# HDSC_HC32L110 register map
Vendor: HDSC Co.Ltd; Series: ARMCM0P; File version: 1.2
CPU: CM0 r0p0, little endian, no MPU, no FPU, 3 interrupt priority bits
Registers are 32-bit, read-write, reset 0x0 unless marked. A register's access mark holds for its fields unless they carry their own. Offsets are from the block's base; [hi:lo] are bit positions; {n}, {i} and the like mark numbered series; 'fields as' and 'values as' point back to an identical list.

## I2C
Base 0x40000400
0x00 TMRUN
  [0] TME
0x04 TM
  [7:0] TM
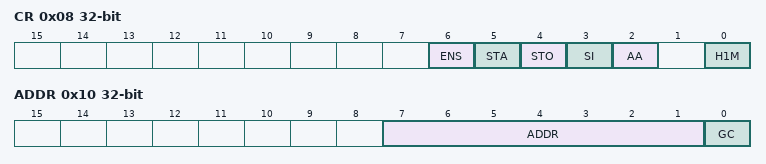
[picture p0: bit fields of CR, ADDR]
0x08 CR
  [6] ENS, [5] STA, [4] STO, [3] SI, [2] AA, [0] H1M
0x0C DATA
  [7:0] DATA
0x10 ADDR
  [7:1] ADDR, [0] GC
0x14 STAT ro
  [7:0] STAT

## LPTIMER
Base 0x40000C00; alternate view of BT0
0x60 CNT ro
  [15:0] CNT
0x64 ARR
  [15:0] ARR
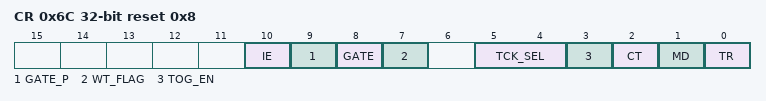
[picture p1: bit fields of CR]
0x6C CR reset 0x8
  [10] IE, [9] GATE_P, [8] GATE, [7] WT_FLAG ro, [5:4] TCK_SEL, [3] TOG_EN, [2] CT, [1] MD, [0] TR
0x70 IFR ro
  [0] TF
0x74 ICLR wo
  [0] TFC

## LPUART
Base 0x40000200
0x00 SBUF
  [7:0] SBUF
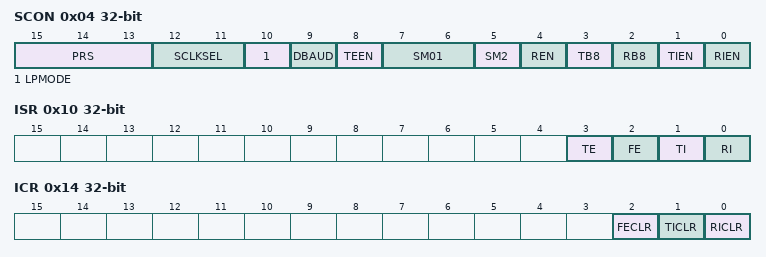
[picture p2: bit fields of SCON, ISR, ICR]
0x04 SCON
  [15:13] PRS, [12:11] SCLKSEL, [10] LPMODE, [9] DBAUD, [8] TEEN, [7:6] SM01, [5] SM2, [4] REN, [3] TB8, [2] RB8, [1] TIEN, [0] RIEN
0x08 SADDR
  [7:0] SADDR
0x0C SADEN
  [7:0] SADEN
0x10 ISR ro
  [3] TE, [2] FE, [1] TI, [0] RI
0x14 ICR wo
  [2] FECLR, [1] TICLR, [0] RICLR

## LVD
Base 0x40002400; alternate view of ADC
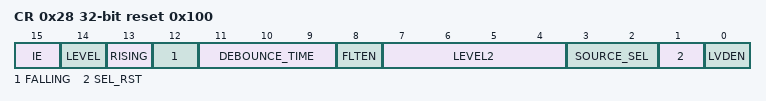
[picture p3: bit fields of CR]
0x28 CR reset 0x100
  [15] IE, [14] LEVEL, [13] RISING, [12] FALLING, [11:9] DEBOUNCE_TIME, [8] FLTEN, [7:4] LEVEL2, [3:2] SOURCE_SEL, [1] SEL_RST, [0] LVDEN
0x2C IFR
  [0] INTF

## PCA
Base 0x40001000
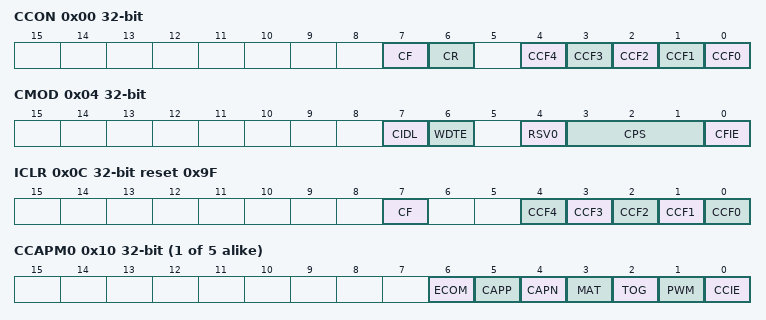
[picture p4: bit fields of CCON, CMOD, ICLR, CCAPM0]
0x00 CCON
  [7] CF, [6] CR, [n] CCF{n} (n=0..4)
0x04 CMOD
  [7] CIDL, [6] WDTE, [4] RSV0, [3:1] CPS, [0] CFIE
0x08 CNT
  [15:0] CNT
0x0C ICLR wo reset 0x9F
  [7] CF, [n] CCF{n} (n=0..4)
{0x10+4i} CCAPM{i} (i=0..4)
  [6] ECOM, [5] CAPP, [4] CAPN, [3] MAT, [2] TOG, [1] PWM, [0] CCIE
{0x24+8i} CCAP{i}H (i=0..4)
  [7:0] CCAP{i}
{0x28+8i} CCAP{i}L (i=0..4)
  [7:0] CCAP{i}
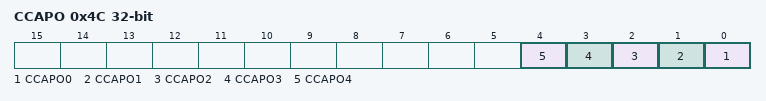
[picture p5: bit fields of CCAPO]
0x4C CCAPO
  [n] CCAPO{n} (n=0..4)
{0x50+4i} CCAP{i} (i=0..4)
  [15:0] CCAP{i}

## RAM
Base 0x40020400
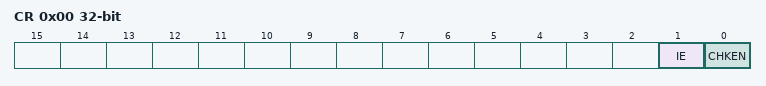
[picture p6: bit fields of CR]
0x00 CR
  [1] IE, [0] CHKEN
0x04 ERRADDR ro
  [11:0] ERRADDR
0x08 IFR ro
  [0] ERR
0x0C ICLR ro
  [0] ERRCLR wo

## RESET
Base 0x4000201C
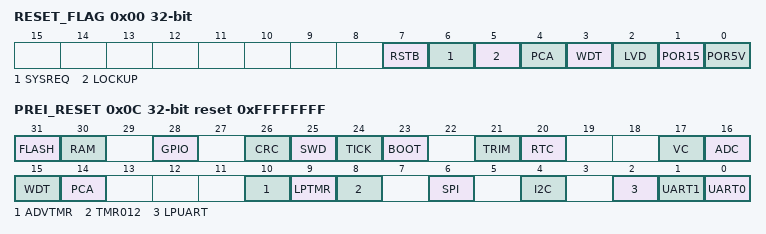
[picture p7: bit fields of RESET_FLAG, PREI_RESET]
0x00 RESET_FLAG
  [7] RSTB, [6] SYSREQ, [5] LOCKUP, [4] PCA, [3] WDT, [2] LVD, [1] POR15, [0] POR5V
0x0C PREI_RESET reset 0xFFFFFFFF
  [31] FLASH, [30] RAM, [28] GPIO, [26] CRC, [25] SWD, [24] TICK, [23] BOOT, [21] TRIM, [20] RTC, [17] VC, [16] ADC, [15] WDT, [14] PCA, [10] ADVTMR, [9] LPTMR, [8] TMR012, [6] SPI, [4] I2C, [2] LPUART, [1] UART1, [0] UART0

## RTC
Base 0x40001400
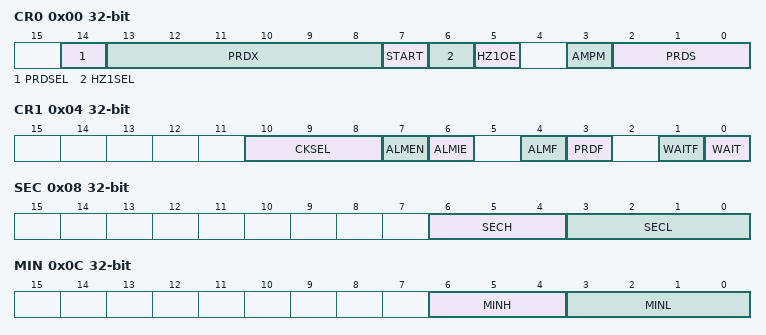
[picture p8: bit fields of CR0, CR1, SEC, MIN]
0x00 CR0
  [14] PRDSEL, [13:8] PRDX, [7] START, [6] HZ1SEL, [5] HZ1OE, [3] AMPM, [2:0] PRDS
0x04 CR1
  [10:8] CKSEL, [7] ALMEN, [6] ALMIE, [4] ALMF, [3] PRDF, [1] WAITF, [0] WAIT
0x08 SEC
  [6:4] SECH, [3:0] SECL
0x0C MIN
  [6:4] MINH, [3:0] MINL
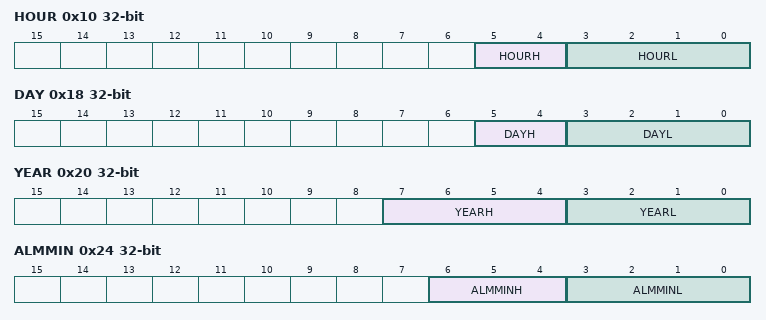
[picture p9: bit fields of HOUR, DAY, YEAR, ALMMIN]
0x10 HOUR
  [5:4] HOURH, [3:0] HOURL
0x14 WEEK
  [2:0] WEEK
0x18 DAY
  [5:4] DAYH, [3:0] DAYL
0x1C MON
  [4:0] MON
0x20 YEAR
  [7:4] YEARH, [3:0] YEARL
0x24 ALMMIN
  [6:4] ALMMINH, [3:0] ALMMINL
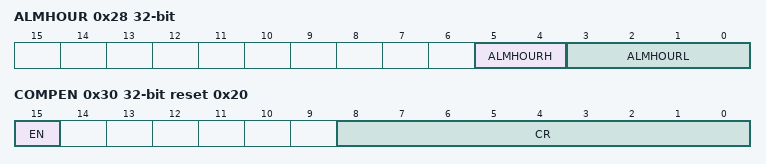
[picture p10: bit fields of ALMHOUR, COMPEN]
0x28 ALMHOUR
  [5:4] ALMHOURH, [3:0] ALMHOURL
0x2C ALMWEEK
  [6:0] ALMWEEK
0x30 COMPEN reset 0x20
  [15] EN, [8:0] CR

## SPI
Base 0x40000800
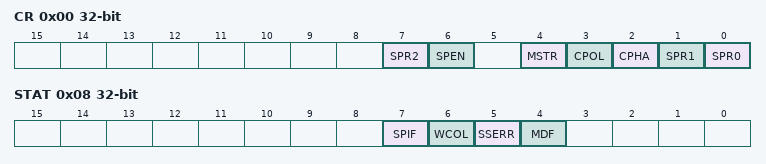
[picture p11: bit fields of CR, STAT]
0x00 CR
  [7] SPR2, [6] SPEN, [4] MSTR, [3] CPOL, [2] CPHA, [1] SPR1, [0] SPR0
0x04 SSN
  [0] SSN
0x08 STAT ro
  [7] SPIF, [6] WCOL, [5] SSERR, [4] MDF
0x0C DATA
  [7:0] DATA

## UART0 — desc UART
Base 0x40000000
Same registers: UART1 0x40000100
0x00 SBUF
  [7:0] SBUF
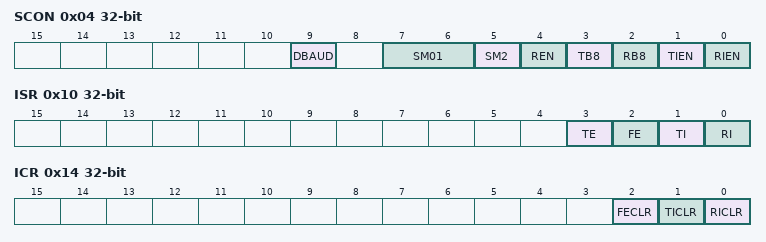
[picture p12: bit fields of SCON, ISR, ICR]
0x04 SCON
  [9] DBAUD, [7:6] SM01, [5] SM2, [4] REN, [3] TB8, [2] RB8, [1] TIEN, [0] RIEN
0x08 SADDR
  [7:0] SADDR
0x0C SADEN
  [7:0] SADEN
0x10 ISR ro
  [3] TE, [2] FE, [1] TI, [0] RI
0x14 ICR wo
  [2] FECLR, [1] TICLR rw, [0] RICLR rw

## VC
Base 0x40002400; alternate view of ADC
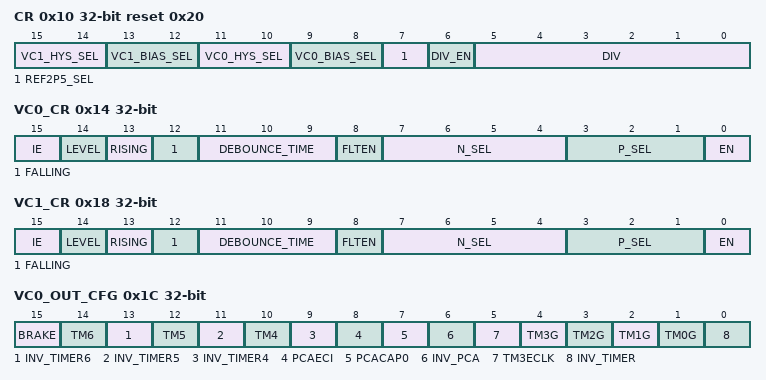
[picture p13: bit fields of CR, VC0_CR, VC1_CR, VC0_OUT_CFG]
0x10 CR reset 0x20
  [15:14] VC1_HYS_SEL, [13:12] VC1_BIAS_SEL, [11:10] VC0_HYS_SEL, [9:8] VC0_BIAS_SEL, [7] REF2P5_SEL, [6] DIV_EN, [5:0] DIV
0x14 VC0_CR
  [15] IE, [14] LEVEL, [13] RISING, [12] FALLING, [11:9] DEBOUNCE_TIME, [8] FLTEN, [7:4] N_SEL, [3:1] P_SEL, [0] EN
0x18 VC1_CR
  fields as VC0_CR
0x1C VC0_OUT_CFG
  [15] BRAKE, [14] TM6, [13] INV_TIMER6, [12] TM5, [11] INV_TIMER5, [10] TM4, [9] INV_TIMER4, [8] PCAECI, [7] PCACAP0, [6] INV_PCA, [5] TM3ECLK, [n+1] TM{n}G (n=0..3), [0] INV_TIMER
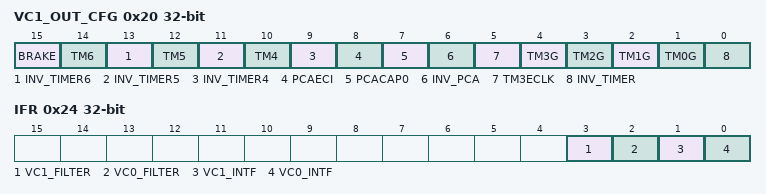
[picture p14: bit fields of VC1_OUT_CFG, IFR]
0x20 VC1_OUT_CFG
  fields as VC0_OUT_CFG
0x24 IFR
  [3] VC1_FILTER ro, [2] VC0_FILTER ro, [1] VC1_INTF, [0] VC0_INTF

## WDT
Base 0x40000C00; alternate view of BT0
0x80 WDTRST wo
  [7:0] WDTRST
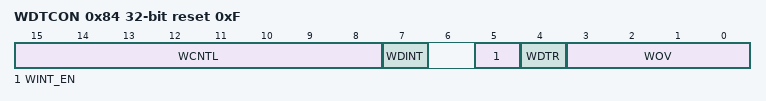
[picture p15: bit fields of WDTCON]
0x84 WDTCON reset 0xF
  [15:8] WCNTL ro, [7] WDINT ro, [5] WINT_EN, [4] WDTR ro, [3:0] WOV
